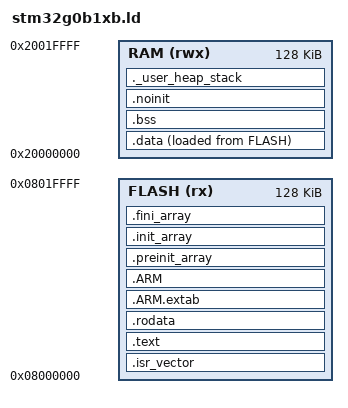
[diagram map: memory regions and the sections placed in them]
/*
 * Linker script for STM32G0B1xB (128 KB flash). Also used for the Nucleo's
 * G0B1RE (512 KB flash): we simply don't use the upper flash there.
 *
 * RAM: the G0B1 has 144 KB of SRAM, but only 128 KB if the SRAM parity option
 * bit is enabled. Using 128 KB works either way; this firmware needs ~30 KB.
 */
ENTRY(Reset_Handler)

MEMORY
{
    FLASH (rx)  : ORIGIN = 0x08000000, LENGTH = 128K
    RAM   (rwx) : ORIGIN = 0x20000000, LENGTH = 128K
}

_estack = ORIGIN(RAM) + LENGTH(RAM);
_Min_Stack_Size = 0x1000;   /* 4 KB; checked at link time below */

SECTIONS
{
    .isr_vector :
    {
        . = ALIGN(4);
        KEEP(*(.isr_vector))
        . = ALIGN(4);
    } > FLASH

    .text :
    {
        . = ALIGN(4);
        *(.text)
        *(.text*)
        *(.glue_7)
        *(.glue_7t)
        *(.eh_frame)
        KEEP(*(.init))
        KEEP(*(.fini))
        . = ALIGN(4);
        _etext = .;
    } > FLASH

    .rodata :
    {
        . = ALIGN(4);
        *(.rodata)
        *(.rodata*)
        . = ALIGN(4);
    } > FLASH

    .ARM.extab (READONLY) : { *(.ARM.extab* .gnu.linkonce.armextab.*) } > FLASH
    .ARM (READONLY) :
    {
        __exidx_start = .;
        *(.ARM.exidx*)
        __exidx_end = .;
    } > FLASH

    .preinit_array (READONLY) :
    {
        PROVIDE_HIDDEN(__preinit_array_start = .);
        KEEP(*(.preinit_array*))
        PROVIDE_HIDDEN(__preinit_array_end = .);
    } > FLASH

    .init_array (READONLY) :
    {
        PROVIDE_HIDDEN(__init_array_start = .);
        KEEP(*(SORT(.init_array.*)))
        KEEP(*(.init_array*))
        PROVIDE_HIDDEN(__init_array_end = .);
    } > FLASH

    .fini_array (READONLY) :
    {
        PROVIDE_HIDDEN(__fini_array_start = .);
        KEEP(*(SORT(.fini_array.*)))
        KEEP(*(.fini_array*))
        PROVIDE_HIDDEN(__fini_array_end = .);
    } > FLASH

    _sidata = LOADADDR(.data);

    .data :
    {
        . = ALIGN(4);
        _sdata = .;
        *(.data)
        *(.data*)
        *(.RamFunc)
        *(.RamFunc*)
        . = ALIGN(4);
        _edata = .;
    } > RAM AT > FLASH

    .bss :
    {
        . = ALIGN(4);
        _sbss = .;
        __bss_start__ = _sbss;
        *(.bss)
        *(.bss*)
        *(COMMON)
        . = ALIGN(4);
        _ebss = .;
        __bss_end__ = _ebss;
    } > RAM

    /* Not zeroed at reset: carries the "reboot into DFU" request (system.c). */
    .noinit (NOLOAD) :
    {
        . = ALIGN(4);
        *(.noinit)
        *(.noinit*)
        . = ALIGN(4);
    } > RAM

    /* Heap (unused: no malloc) and stack. Fails the link if RAM is too small. */
    ._user_heap_stack (NOLOAD) :
    {
        . = ALIGN(8);
        PROVIDE(end = .);
        PROVIDE(_end = .);
        . = . + _Min_Stack_Size;
        . = ALIGN(8);
    } > RAM

    .ARM.attributes 0 : { *(.ARM.attributes) }
}
